# PRCM_MPU_PRM_C1 register map
Vendor: Texas Instruments
Peripheral module from a debugger description file (folder omap5430_ES2_PUBLIC).
Registers are 32-bit, access not given, reset 0x0 unless marked. A register's access mark holds for its fields unless they carry their own. Offsets are as the file gives them; lines under a group give offsets from that group; [hi:lo] are bit positions; {n}, {i} and the like mark numbered series; 'fields as' and 'values as' point back to an identical list; <NAME> marks a mode.

## PRCM_MPU_PRM_C1
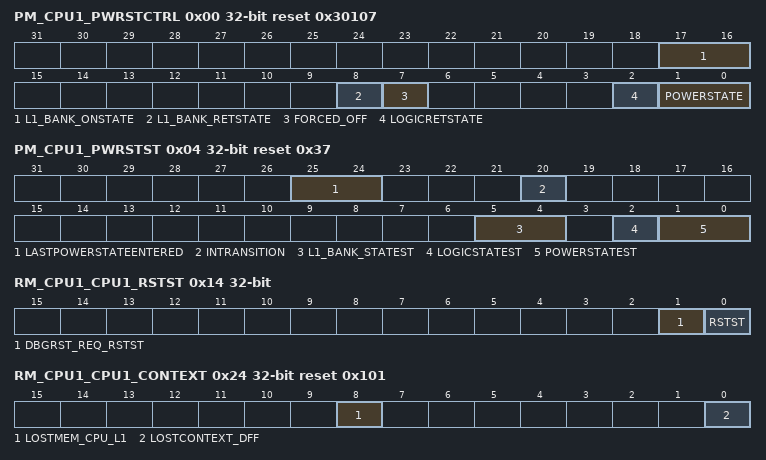
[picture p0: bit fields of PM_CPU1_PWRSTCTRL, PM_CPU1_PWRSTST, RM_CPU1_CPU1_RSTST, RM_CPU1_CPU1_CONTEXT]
0x00 PM_CPU1_PWRSTCTRL reset 0x30107 — This register controls the CPU domain power state to reach upon a domain sleep transition
  [17:16] L1_BANK_ONSTATE — CPU_L1 memory state when domain is ON. (access R Rreturns1s)
    3=Mem_on (Memory bank is on when the domain is ON.)
  [8] L1_BANK_RETSTATE — CPU L1 memory state when domain is RETENTION. (access R Rreturns1s)
    1=mem_ret (Memory bank is retained when domain is in RETENTION state.)
  [7] FORCED_OFF rw — Selects if logic must be forced in OFF state.
    0=OFF_not_forced (Whole logic is not forced in OFF state.); 1=OFF_forced (Whole logic is forced in OFF state.)
  [2] LOGICRETSTATE — Logic state when power domain is RETENTION (access R Rreturns1s)
    1=logic_ret (Whole logic is retained when domain is in RETENTION state.)
  [1:0] POWERSTATE rw — Power state control
    0=OFF (OFF state); 1=RET (RETENTION state); 3=ON (ON state); 2=INACT (INACTIVE state)
0x04 PM_CPU1_PWRSTST reset 0x37 — This register provides a status on the CPU domain current power state. [warm reset insensitive]
  [25:24] LASTPOWERSTATEENTERED — Last low-power state entered (access RW W1toSet)
    0=OFF (Power domain was previously OFF.); 1=RET (Power domain was previously in RETENTION.); 3=ON (Power domain was previously ON.); 2=INACT (Power domain previously was INACTIVE.)
  [20] INTRANSITION ro — Domain transition status
    1=Ongoing (Power domain transition is in progress.); 0=No (No ongoing transition on power domain)
  [5:4] L1_BANK_STATEST ro — CPU_L1 memory state status
    3=Mem_on (Memory is ON.); 1=Mem_ret (Memory is RET.); 0=Mem_off (Memory is OFF.)
  [2] LOGICSTATEST ro — Logic state status
    1=ON (Logic in domain is ON.); 0=OFF (Logic in domain is OFF.)
  [1:0] POWERSTATEST ro — Current power state status
    3=ON (Power domain is ON-ACTIVE.); 2=INACTIVE (Power domain is ON-INACTIVE.); 1=RET (Power domain is in RETENTION.); 0=OFF (Power domain is OFF.)
0x10 RM_CPU1_CPU1_RSTCTRL access per field — This register controls the assertion/release of the CPU CORE reset.
  [0] RST rw — CPU warm local reset control
    0=CLEAR (Reset is cleared.); 1=ASSERT (Reset is asserted.)
0x14 RM_CPU1_CPU1_RSTST — This register logs the different reset sources of the MPU domain. Each bit is set upon release of the domain reset signal. Must be cleared by software. [warm reset insensitive]
  [1] DBGRST_REQ_RSTST — MPU_C1 processor has been reset due to MPU_C0 emulation reset request driven from MPUSS (access RW W1toClr)
    1=ASSERT (MPU_C1 has been reset upon emulation request.); 0=CLEAR (No emulation reset)
  [0] RSTST — MPU_C1 software reset (access RW W1toClr)
    1=ASSERT (MPU_C1 has been reset upon software reset.); 0=CLEAR (No software reset occurred.)
0x24 RM_CPU1_CPU1_CONTEXT reset 0x101 — This register contains dedicated CPU context statuses. [warm reset insensitive]
  [8] LOSTMEM_CPU_L1 — Specify if memory-based context in CPU_L1 memory bank has been lost due to a previous power transition or other reset source. (access RW W1toClr)
    0=Maintained (Context has been maintained.); 1=Lost (Context has been lost.)
  [0] LOSTCONTEXT_DFF — Specify if DFF-based context has been lost due to a previous power transition or other reset source. (access RW W1toClr)
    values as LOSTMEM_CPU_L1
